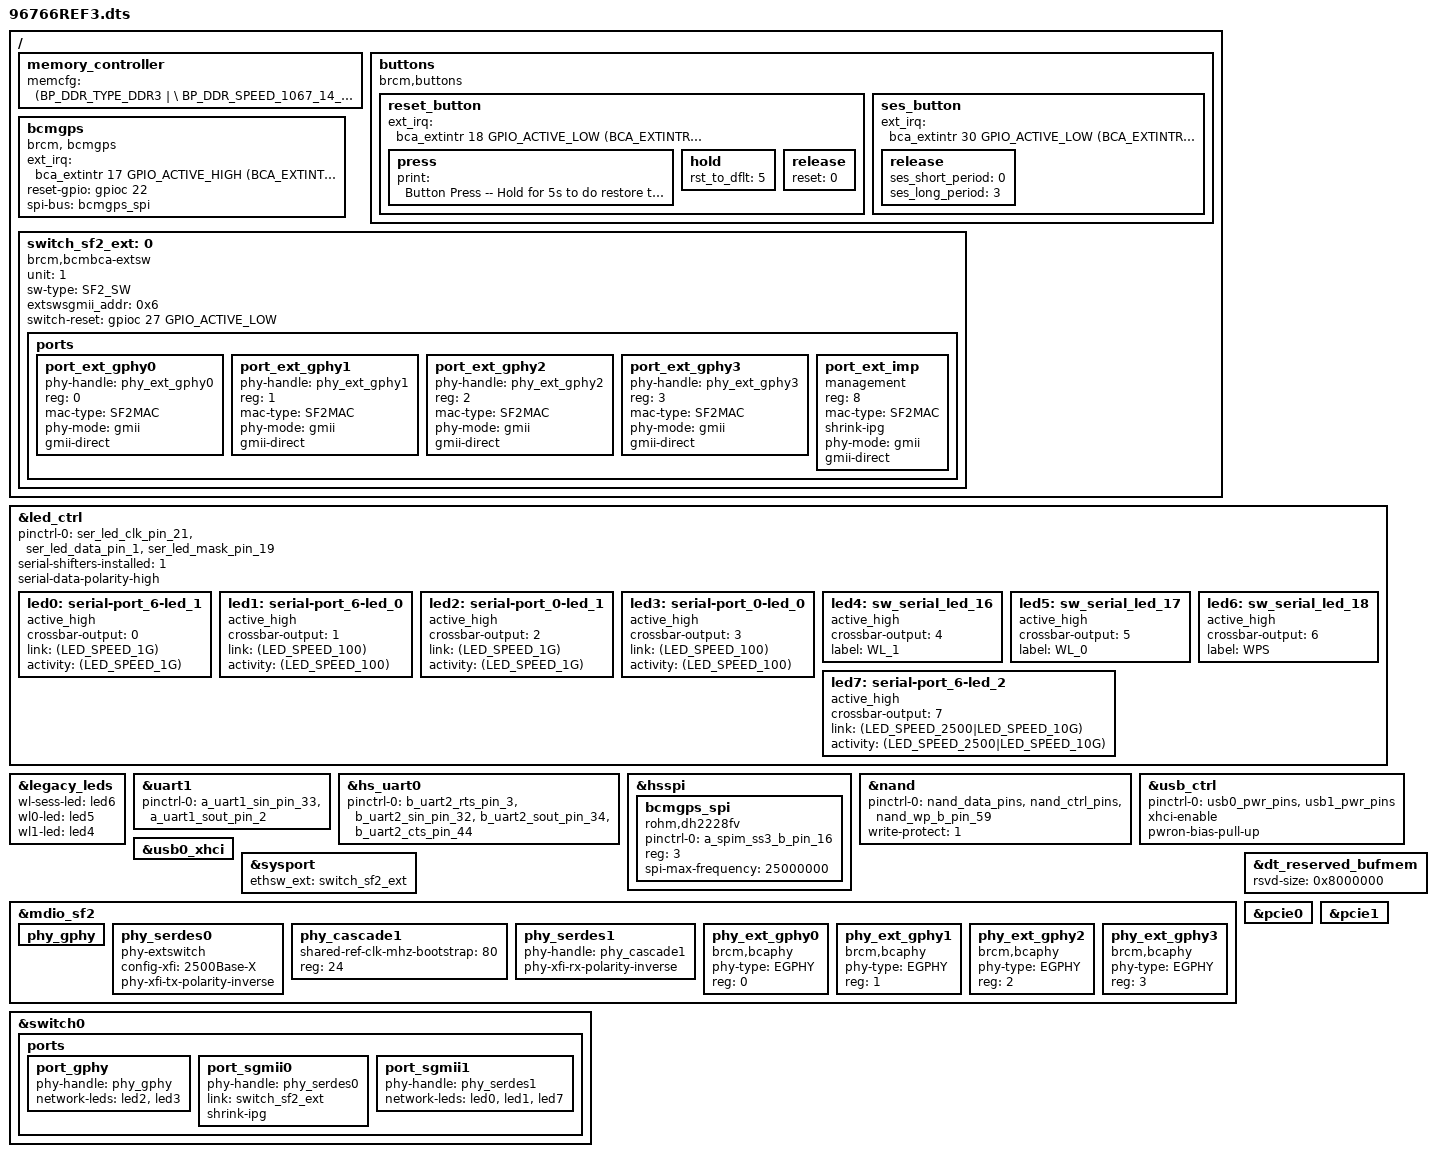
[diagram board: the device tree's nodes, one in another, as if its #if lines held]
#include "6766.dtsi"

/ {
	memory_controller {
		memcfg = <(BP_DDR_TYPE_DDR3       | \
			BP_DDR_SPEED_1067_14_14_14    | \
			BP_DDR_TOTAL_SIZE_512MB      | \
			BP_DDR_DEVICE_WIDTH_16        | \
			BP_DDR_TOTAL_WIDTH_16BIT      | \
			BP_DDR_6766_DEFAULT           | \
			BP_DDR_CONFIG_DEBUG)>;
	};

	buttons {
		compatible = "brcm,buttons";

		reset_button {
			ext_irq = <&bca_extintr 18 GPIO_ACTIVE_LOW (BCA_EXTINTR_TYPE_LOW_LEVEL | BCA_EXTINTR_TYPE_SENSE_EDGE)>;
			press {
				print = "Button Press -- Hold for 5s to do restore to default";
			};
			hold {
				rst_to_dflt = <5>;
			};
			release {
				reset = <0>;
			};
		};

		ses_button {
			ext_irq = <&bca_extintr 30 GPIO_ACTIVE_LOW (BCA_EXTINTR_TYPE_LOW_LEVEL | BCA_EXTINTR_TYPE_SENSE_EDGE)>;
			release {
				ses_short_period = <0>;
				ses_long_period = <3>;
			};
		};
	};

	bcmgps: bcmgps {
		compatible = "brcm, bcmgps";
		ext_irq = <&bca_extintr 17 GPIO_ACTIVE_HIGH (BCA_EXTINTR_TYPE_HIGH_LEVEL | BCA_EXTINTR_TYPE_SENSE_EDGE)>;   /* host_req */
		reset-gpio = <&gpioc 22 GPIO_ACTIVE_HIGH>;  /* nStandby */
		spi-bus = <&bcmgps_spi>;
		status = "okay";
	};

	switch_sf2_ext:0 {
	};
};

&led_ctrl {
	pinctrl-names = "default";
	pinctrl-0 = <&ser_led_clk_pin_21 &ser_led_data_pin_1 &ser_led_mask_pin_19>;
	serial-shifters-installed = <1>;
	serial-data-polarity-high;

	led0: serial-port_6-led_1 {
		active_high;
		crossbar-output = <0>;
		link = <(LED_SPEED_1G)>;
		activity = <(LED_SPEED_1G)>;
		status = "okay";
	};

	led1: serial-port_6-led_0 {
		active_high;
		crossbar-output = <1>;
		link = <(LED_SPEED_100)>;
		activity = <(LED_SPEED_100)>;
		status = "okay";
	};

	led2: serial-port_0-led_1 {
		active_high;
		crossbar-output = <2>;
		link = <(LED_SPEED_1G)>;
		activity = <(LED_SPEED_1G)>;
		status = "okay";
	};

	led3: serial-port_0-led_0 {
		active_high;
		crossbar-output = <3>;
		link = <(LED_SPEED_100)>;
		activity = <(LED_SPEED_100)>;
		status = "okay";
	};

	led4: sw_serial_led_16 {
		active_high;
		crossbar-output = <4>;
		status = "okay";
		label = "WL_1";
	};

	led5: sw_serial_led_17 {
		active_high;
		crossbar-output = <5>;
		status = "okay";
		label = "WL_0";
	};

	led6: sw_serial_led_18 {
		active_high;
		crossbar-output = <6>;
		status = "okay";
		label = "WPS";
	};

	led7: serial-port_6-led_2 {
		active_high;
		crossbar-output = <7>;
		link = <(LED_SPEED_2500|LED_SPEED_10G)>;
		activity = <(LED_SPEED_2500|LED_SPEED_10G)>;
		status = "okay";
	};
};

&legacy_leds {
	wl-sess-led = <&led6>;
	wl0-led = <&led5>;
	wl1-led = <&led4>;
};

&uart1 {
	pinctrl-names = "default";
	pinctrl-0 = <&a_uart1_sin_pin_33 &a_uart1_sout_pin_2>;
	status = "okay";
};

&hs_uart0 {
	pinctrl-0 = <&b_uart2_rts_pin_3 &b_uart2_sin_pin_32 &b_uart2_sout_pin_34 &b_uart2_cts_pin_44>;
	pinctrl-names = "default";
	status = "okay";
};

&hsspi {
	status = "okay";
	bcmgps_spi: bcmgps_spi {
		pinctrl-names = "default";
		pinctrl-0 = <&a_spim_ss3_b_pin_16>;
		status = "okay";
		compatible = "rohm,dh2228fv";
		reg = <3>;
		spi-max-frequency = <25000000>;
	};
};

&nand {
	pinctrl-0 = <&nand_data_pins &nand_ctrl_pins &nand_wp_b_pin_59>;
	write-protect = <1>;
	status = "okay";
};

&usb_ctrl {
    pinctrl-names="default";
    pinctrl-0 = <&usb0_pwr_pins &usb1_pwr_pins>;
    status = "okay";
    xhci-enable;
    pwron-bias-pull-up;
};

&usb0_xhci {
    status = "okay";
};

&sysport {
	ethsw_ext = <&switch_sf2_ext>;
};

&mdio_sf2 {
		/* Port PHY mapping:
            port_imp -8#0- port_gphy <----> phy_gphy
                      # 6- port_sgmii1 <--> phy_serdes1 - phy_cascade1
                      ##5- port_sgmii0 <--> phy_serdes0 <--> port_ext_imp -8#0- port_ext_gphy0 <--> phy_ext_gphy0
                                                                           # 1- port_ext_gphy1 <--> phy_ext_gphy1
                                                                           # 2- port_ext_gphy2 <--> phy_ext_gphy2
                                                                           ##3- port_ext_gphy3 <--> phy_ext_gphy3
		 */
	phy_gphy {
		status = "okay";
	};

	phy_serdes0 {
		phy-extswitch;
		config-xfi="2500Base-X";
		phy-xfi-tx-polarity-inverse;
		status = "okay";
	};
	phy_cascade1 {
		shared-ref-clk-mhz-bootstrap = <80>;
        reg = <24>;
		status = "okay";
	};
	phy_serdes1 {
		phy-handle = <&phy_cascade1>;
		phy-xfi-rx-polarity-inverse;
		status = "okay";
	};

	/* PHYs on external SF2 switch */
	phy_ext_gphy0:phy_ext_gphy0 {
		compatible = "brcm,bcaphy";
		phy-type = "EGPHY";
		reg = <0>;
		status = "okay";
	};
	phy_ext_gphy1:phy_ext_gphy1 {
		compatible = "brcm,bcaphy";
		phy-type = "EGPHY";
		reg = <1>;
		status = "okay";
	};
	phy_ext_gphy2:phy_ext_gphy2 {
		compatible = "brcm,bcaphy";
		phy-type = "EGPHY";
		reg = <2>;
		status = "okay";
	};
	phy_ext_gphy3:phy_ext_gphy3 {
		compatible = "brcm,bcaphy";
		phy-type = "EGPHY";
		reg = <3>;
		status = "okay";
	};
};

&switch_sf2_ext {                       /* linux/uboot: external sf2 */
	unit = <1>;
	sw-type = "SF2_SW";

	compatible = "brcm,bcmbca-extsw";
	extswsgmii_addr = <0x6>;
	switch-reset = <&gpioc 27 GPIO_ACTIVE_LOW>;

	ports {
		#address-cells = <1>;
		#size-cells = <0>;

		port_ext_gphy0 {
			phy-handle = <&phy_ext_gphy0>;
			reg = <0>;
			mac-type = "SF2MAC";
			phy-mode = "gmii";
			gmii-direct;
			status = "okay";
		};
		port_ext_gphy1 {
			phy-handle = <&phy_ext_gphy1>;
			reg = <1>;
			mac-type = "SF2MAC";
			phy-mode = "gmii";
			gmii-direct;
			status = "okay";
		};
		port_ext_gphy2 {
			phy-handle = <&phy_ext_gphy2>;
			reg = <2>;
			mac-type = "SF2MAC";
			phy-mode = "gmii";
			gmii-direct;
			status = "okay";
		};
		port_ext_gphy3 {
			phy-handle = <&phy_ext_gphy3>;
			reg = <3>;
			mac-type = "SF2MAC";
			phy-mode = "gmii";
			gmii-direct;
			status = "okay";
		};
		port_ext_imp {
			management;                     /* sf2_ext.p8 <--> root.p5  when P8_SGMII_SEL=1 */
			reg = <8>;
			mac-type = "SF2MAC";
			shrink-ipg;
			phy-mode = "gmii";
			gmii-direct;
			status = "okay";
		};
	};
};

&switch0 {

	ports {
		port_gphy {
			phy-handle = <&phy_gphy>;
			network-leds=<&led2 &led3>;
			status = "okay";
		};
		port_sgmii0 {
			phy-handle = <&phy_serdes0>;
			link = <&switch_sf2_ext>;
			shrink-ipg;
			status = "okay";
		};
		port_sgmii1 {
			phy-handle = <&phy_serdes1>;
			network-leds=<&led0 &led1 &led7>;
			status = "okay";
		};
	};
};

#if defined(CONFIG_BCM_MPM) || defined(CONFIG_BCM_MPM_MODULE)
&dt_reserved_bufmem {
	rsvd-size = <0x8000000>;
};
#endif

#if defined(CONFIG_BCM_PCIE_HCD) || defined(CONFIG_BCM_PCIE_HCD_MODULE)
/**********************************************************************/
/* GPIO: Add one define per GPIO (individual or shared) regulator     */
/*       - Skip if no GPIO regulators in use                          */
/**********************************************************************/
#define PCIE0_REG_GPIO    15   /* PCIE0_PWR_CTRL for vreg_pcie0 node */
#define PCIE1_REG_GPIO    6    /* PCIE1_PWR_CTRL for vreg_pcie1 node */

#include "../bcm_wlan_regulator.dtsi"

/**********************************************************************/
/* Shared: Add brcm,supply-names = "vreg-pcieX" for shared PCIe nodes */
/*         - Skip if not using shared GPIO regulators                 */
/**********************************************************************/

/**********************************************************************/
/* PCIe: Add status = "okay" for each PCIe slots of this boiard       */
/*       - Skip if this is a derivative board (already done in base)  */
/**********************************************************************/
&pcie0 {
	status = "okay";
};

&pcie1 {
	status = "okay";
};
#endif //#if defined(CONFIG_BCM_PCIE_HCD) || defined(CONFIG_BCM_PCIE_HCD_MODULE)
